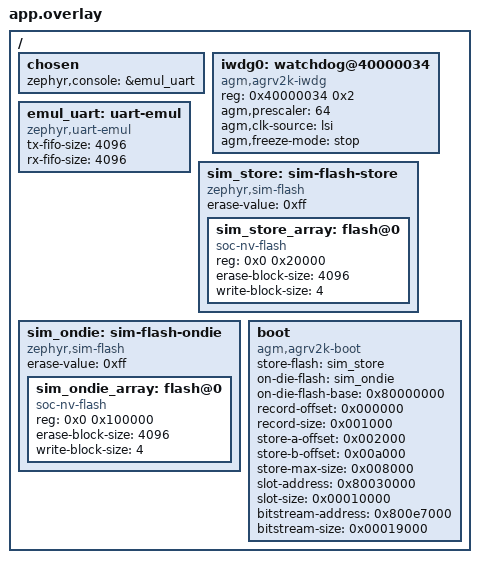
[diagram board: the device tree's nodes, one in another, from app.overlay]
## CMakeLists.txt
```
# SPDX-License-Identifier: Apache-2.0

cmake_minimum_required(VERSION 3.20.0)
find_package(Zephyr REQUIRED HINTS $ENV{ZEPHYR_BASE})
project(boot_agm_rsa)

target_sources(app PRIVATE src/main.c)

# Embed the signed-image fixtures (generated once with `imgtool sign`)
# as C arrays: the test pushes them into a simulated flash
# through the driver's own upload API, exactly like a host would.
function(agm_embed_bin out_c sym file size)
	# (${out_c} goes to the app target when it defines a symbol the driver also
	# defines weakly -- see the call for agm_boot_pubkey below.)
	file(READ "${file}" _hex HEX)
	string(REGEX REPLACE "(..)" "0x\\1," _bytes "${_hex}")
	if(size GREATER 0)
		set(_decl "const unsigned char ${sym}[${size}]")
	else()
		string(LENGTH "${_hex}" _hex_len)
		math(EXPR _n "${_hex_len} / 2")
		set(_decl "const unsigned char ${sym}[${_n}]")
	endif()
	file(WRITE "${out_c}"
"/* Generated from ${file} -- do not edit. */
#include <stddef.h>
${_decl} = {
${_bytes}
};
const size_t ${sym}_len = sizeof(${sym});
")
	zephyr_library_sources("${out_c}")
	set(AGM_LAST_GENERATED "${out_c}" PARENT_SCOPE)
endfunction()

# The driver defines `agm_boot_pubkey` weakly, and a strong definition inside
# libzephyr would not replace it: this one has to live in the app target. The
# RSA profile keeps the 270-byte PKCS#1 DER (AGM_BOOT_PUBKEY_LEN).
function(agm_embed_pubkey sym file)
	agm_embed_bin(${CMAKE_CURRENT_BINARY_DIR}/fx_pubkey.c ${sym} ${file} 270)
	target_sources(app PRIVATE "${CMAKE_CURRENT_BINARY_DIR}/fx_pubkey.c")
endfunction()

set(FIX ${CMAKE_CURRENT_SOURCE_DIR}/fixtures)
agm_embed_bin(${CMAKE_CURRENT_BINARY_DIR}/fx_signed_ok.c agm_signed_ok ${FIX}/signed_ok.bin 0)
agm_embed_bin(${CMAKE_CURRENT_BINARY_DIR}/fx_signed_other_key.c agm_signed_other_key ${FIX}/signed_other_key.bin 0)
agm_embed_bin(${CMAKE_CURRENT_BINARY_DIR}/fx_signed_other_slot.c agm_signed_other_slot ${FIX}/signed_other_slot.bin 0)
agm_embed_bin(${CMAKE_CURRENT_BINARY_DIR}/fx_raw.c agm_image_raw ${FIX}/image.bin 0)
# The ECDSA suite's signed_ok.bin, byte for byte: the *other* profile's
# container, which an RSA build has to refuse.
agm_embed_bin(${CMAKE_CURRENT_BINARY_DIR}/fx_ecdsa_signed.c agm_ecdsa_signed ${FIX}/ecdsa_signed.bin 0)
# The trusted key the driver verifies with.
agm_embed_pubkey(agm_boot_pubkey ${FIX}/pubkey.bin)
```

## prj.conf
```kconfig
# SPDX-License-Identifier: Apache-2.0
#
# The bootloader driver in its signed mode, RSA-2048-PSS flavour: images must be
# MCUboot containers signed with the fixture key (see fixtures/README.md).

CONFIG_ZTEST=y

CONFIG_FLASH=y
CONFIG_FLASH_SIMULATOR=y
CONFIG_FLASH_PAGE_LAYOUT=y
CONFIG_CRC=y
CONFIG_BOOT_AGM=y
CONFIG_BOOT_AGM_SIG_RSA2048_PSS=y

# No console protocols here; the driver still wants the console device.
CONFIG_BOOT_AGM_ONESHOT=n
CONFIG_BOOT_AGM_AN3155=n
CONFIG_SERIAL=y
# app.overlay points the console at a zephyr,uart-emul (the driver only needs
# *a* console device; this one needs no pty).
CONFIG_EMUL=y
CONFIG_UART_EMUL=y

CONFIG_MAIN_STACK_SIZE=8192
CONFIG_ZTEST_STACK_SIZE=8192

# Note: no MBEDTLS_ENABLE_HEAP here. PSA stores key material in statically
# allocated slots by default (MBEDTLS_PSA_STATIC_KEY_SLOTS), which is what a
# bootloader that imports one 270-byte public key wants -- no heap, no
# allocator in the loader's footprint.
#
# Only two of those slots: the default 16 are sized for the largest enabled
# key type and this driver imports exactly one key, so the rest is ~7.9 KB of
# RAM spent on nothing.
CONFIG_MBEDTLS_PSA_KEY_SLOT_COUNT=2
```

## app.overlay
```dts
/* SPDX-License-Identifier: Apache-2.0 */
/*
 * Devicetree for the native boot-driver test: two simulated flashes stand in
 * for the on-board SPI NOR (record + A/B stores + bitstream staging) and the
 * on-die flash (application slot + fabric reservation), and the boot node
 * describes a small layout on top of them.
 *
 * The addresses are the real ones (the on-die flash is mapped at 0x80000000
 * and the application slot sits at 0x80030000, as on the board), so the
 * driver's address-arithmetic -- slot/bitstream addresses vs device offsets,
 * and the "is this container linked for the slot I am writing it to" check --
 * is exercised too. The on-die flash node carries no `reg` (a simulated flash
 * node does not), which is what `on-die-flash-base` is for.
 */

/ {
	/* The console is an emulated UART so the tests can feed the protocol
	 * servers (AN3155, and whatever else uses the console) byte by byte and
	 * read their replies, with no pty and no timing games. */
	chosen {
		zephyr,console = &emul_uart;
	};

	/* The trial-watchdog chain . A simulated IWDG node
	 * makes CONFIG_BOOT_AGM_TRIAL_WATCHDOG selectable here; the test
	 * overrides the driver's weak hooks, so no register is ever touched. */
	iwdg0: watchdog@40000034 {
		compatible = "agm,agrv2k-iwdg";
		reg = <0x40000034 0x2>;
		agm,prescaler = <64>;
		agm,clk-source = "lsi";
		agm,freeze-mode = "stop";
		status = "okay";
	};

	emul_uart: uart-emul {
		compatible = "zephyr,uart-emul";
		status = "okay";
		/* 4 KiB each: the console upload phase prints its progress
		 * through the same emulated UART the protocol replies come
		 * out of, so the TX fifo has to hold a whole session's text
		 * plus the ACK/NAK byte the test looks at. */
		tx-fifo-size = <4096>;
		rx-fifo-size = <4096>;
	};

	sim_store: sim-flash-store {
		compatible = "zephyr,sim-flash";
		erase-value = <0xff>;
		#address-cells = <1>;
		#size-cells = <1>;
		status = "okay";

		sim_store_array: flash@0 {
			compatible = "soc-nv-flash";
			reg = <0x0 0x20000>;
			erase-block-size = <4096>;
			write-block-size = <4>;
		};
	};

	sim_ondie: sim-flash-ondie {
		compatible = "zephyr,sim-flash";
		erase-value = <0xff>;
		#address-cells = <1>;
		#size-cells = <1>;
		status = "okay";

		sim_ondie_array: flash@0 {
			compatible = "soc-nv-flash";
			reg = <0x0 0x100000>;
			erase-block-size = <4096>;
			write-block-size = <4>;
		};
	};

	boot: boot {
		compatible = "agm,agrv2k-boot";
		status = "okay";

		/* Record + stores + bitstream staging: the "external" flash. */
		store-flash = <&sim_store>;
		on-die-flash = <&sim_ondie>;
		on-die-flash-base = <0x80000000>;

		record-offset = <0x000000>;
		record-size = <0x001000>;
		store-a-offset = <0x002000>;
		store-b-offset = <0x00a000>;
		store-max-size = <0x008000>;

		slot-address = <0x80030000>;
		slot-size = <0x00010000>;

		/* The bitstream A/B geometry is the SoC's, not the layout's
		 * (soc/agm/agrv2k/agm_bitstream.h): slot 1 at 0x800b4000,
		 * slot 2 at 0x800cd000, the record sector at 0x800e6000 and
		 * the factory slot at 0x800e7000 -- so the simulated on-die
		 * flash has to be the real 1 MiB. */
		bitstream-address = <0x800e7000>;
		bitstream-size = <0x00019000>;
	};
};
```

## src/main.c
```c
/*
 * Copyright (c) 2026 AgRV Contributors
 * SPDX-License-Identifier: Apache-2.0
 */

/**
 * @file
 * @brief Signed images, RSA flavour: does the loader accept exactly the right
 *        ones?
 *
 * The same five cases as tests/drivers/misc/boot_agm_ecdsa, but against a
 * driver built with CONFIG_BOOT_AGM_SIG_RSA2048_PSS and against RSA fixtures.
 * They differ from the ECDSA ones in exactly the three places the driver has
 * profile-specific code -- the signature TLV type (0x20), the raw 256-byte
 * signature, and the KEYHASH covering the PKCS#1 DER rather than the
 * SubjectPublicKeyInfo -- so running both suites is what keeps those from
 * silently drifting apart:
 *
 *   - a properly signed MCUboot container is accepted;
 *   - one byte of payload flipped is refused (the SHA-256 TLV no longer
 *     matches);
 *   - a container signed by another key is refused (the KEYHASH TLV names a key
 *     this build does not trust);
 *   - a container that is signed by the trusted key but linked for another
 *     address is refused (the header's `ih_load_addr` is not where this layout
 *     would run it);
 *   - a raw image is refused, so a signed build cannot be downgraded by
 *     writing an unsigned one.
 */

#include <zephyr/device.h>
#include <zephyr/drivers/flash.h>
#include <zephyr/drivers/misc/boot_agm.h>
#include <zephyr/drivers/serial/uart_emul.h>
#include <zephyr/sys/byteorder.h>
#include <zephyr/sys/crc.h>
#include <zephyr/ztest.h>

#include <string.h>

#define BOOT_DEV DEVICE_DT_GET(DT_NODELABEL(boot))
#define EMUL     DEVICE_DT_GET(DT_NODELABEL(emul_uart))

extern const unsigned char agm_signed_ok[];
extern const unsigned char agm_signed_other_key[];
extern const unsigned char agm_signed_other_slot[];
extern const unsigned char agm_image_raw[];
extern const unsigned char agm_ecdsa_signed[];
extern const size_t agm_signed_ok_len;
extern const size_t agm_signed_other_key_len;
extern const size_t agm_signed_other_slot_len;
extern const size_t agm_image_raw_len;
extern const size_t agm_ecdsa_signed_len;

/* The fixtures have to be the profile this build verifies with, or the
 * "accepted" case below would be testing nothing. 270 is the PKCS#1 DER of an
 * RSA-2048 key; the ECDSA fixture is 64. */
BUILD_ASSERT(sizeof(agm_boot_pubkey) == 270,
	     "the RSA profile keeps the 270-byte PKCS#1 DER public key");

/* Push bytes into a target through the same API a host uses, tail included:
 * the flash programs whole words, so a real upload finishes with the padded
 * last word (upload_finish() does the same). */
static void place(enum agm_boot_target target, const unsigned char *data,
		  size_t len)
{
	static unsigned char padded[2048];
	size_t total = ROUND_UP(len, 4U);

	zassert_true(total <= sizeof(padded));
	memcpy(padded, data, len);
	memset(padded + len, 0xff, total - len);

	zassert_ok(agm_boot_upload_begin(BOOT_DEV, target), "upload_begin");
	for (size_t off = 0U; off < total; off += 256U) {
		size_t n = MIN(256U, total - off);

		zassert_ok(agm_boot_upload_write(BOOT_DEV, target, (uint32_t)off,
						 padded + off, (uint32_t)n),
			   "upload_write at %u", (unsigned int)off);
	}
}

ZTEST(boot_agm_rsa, test_accepts_a_properly_signed_image)
{
	place(AGM_BOOT_TARGET_STORE_A, agm_signed_ok, agm_signed_ok_len);

	{
		int ret = agm_boot_image_verify(BOOT_DEV, AGM_BOOT_TARGET_STORE_A,
						(uint32_t)agm_signed_ok_len);

		zassert_equal(ret, 0, "verify returned %d", ret);
	}
}

ZTEST(boot_agm_rsa, test_rejects_a_tampered_payload)
{
	static unsigned char tampered[2048];

	zassert_true(agm_signed_ok_len <= sizeof(tampered));
	memcpy(tampered, agm_signed_ok, agm_signed_ok_len);
	tampered[0x40] ^= 0xffU; /* inside the payload; the header is 0x20 bytes */

	place(AGM_BOOT_TARGET_STORE_A, tampered, agm_signed_ok_len);
	zassert_equal(agm_boot_image_verify(BOOT_DEV, AGM_BOOT_TARGET_STORE_A,
					    (uint32_t)agm_signed_ok_len),
		      -EACCES, "a flipped payload byte has to be refused");
}

ZTEST(boot_agm_rsa, test_rejects_another_key)
{
	place(AGM_BOOT_TARGET_STORE_A, agm_signed_other_key, agm_signed_other_key_len);

	zassert_equal(agm_boot_image_verify(BOOT_DEV, AGM_BOOT_TARGET_STORE_A,
					    (uint32_t)agm_signed_other_key_len),
		      -EACCES, "the keyhash TLV has to name a trusted key");
}

ZTEST(boot_agm_rsa, test_rejects_a_raw_image)
{
	place(AGM_BOOT_TARGET_STORE_A, agm_image_raw, agm_image_raw_len);

	zassert_equal(agm_boot_image_verify(BOOT_DEV, AGM_BOOT_TARGET_STORE_A,
					    (uint32_t)agm_image_raw_len),
		      -EINVAL, "a raw image has no MCUboot header");
}

/*
 * Rewrite the signature TLV type to the *other* profile's (RSA2048_PSS 0x20
 * <-> ECDSA_SIG 0x22), leaving the digest, the KEYHASH and the signature bytes
 * as the trusted key signed them: the profile check is the only thing left
 * that can refuse it, from the RSA side.
 */
static void stamp_signature_tlv_as(const uint8_t *src, uint32_t len, uint8_t *dst,
				   uint16_t want_type, uint16_t other_type)
{
	uint16_t hdr_size;
	uint16_t tlv_tot;
	uint32_t img_size;
	uint32_t off;
	uint32_t end;

	zassert_true(len >= 32U, "a container is at least a header");
	memcpy(dst, src, len);
	memcpy(&hdr_size, dst + 8, sizeof(hdr_size));
	memcpy(&img_size, dst + 12, sizeof(img_size));
	off = (uint32_t)hdr_size + img_size; /* the TLV area */

	zassert_true(off + 4U <= len, "the fixture has a TLV area");
	memcpy(&tlv_tot, dst + off + 2, sizeof(tlv_tot));
	end = off + tlv_tot;
	zassert_true(end <= len, "the TLV area fits the container");
	off += 4U;

	while (off + 4U <= end) {
		uint16_t type;
		uint16_t tlen;

		memcpy(&type, dst + off, sizeof(type));
		memcpy(&tlen, dst + off + 2, sizeof(tlen));
		if (type == want_type) {
			memcpy(dst + off, &other_type, sizeof(other_type));
			return;
		}
		off += 4U + tlen;
	}
	zassert_true(false, "no signature TLV in the fixture");
}

ZTEST(boot_agm_rsa, test_rejects_a_container_of_the_other_profile)
{
	place(AGM_BOOT_TARGET_STORE_A, agm_ecdsa_signed, agm_ecdsa_signed_len);

	zassert_equal(agm_boot_image_verify(BOOT_DEV, AGM_BOOT_TARGET_STORE_A,
					    (uint32_t)agm_ecdsa_signed_len),
		      -EACCES, "an ECDSA-signed container is not signed by this key");
}

ZTEST(boot_agm_rsa, test_rejects_a_relabelled_signature_tlv)
{
	static uint8_t patched[2048];

	zassert_true(agm_signed_ok_len <= sizeof(patched));
	stamp_signature_tlv_as(agm_signed_ok, (uint32_t)agm_signed_ok_len, patched,
			       0x20U /* RSA2048_PSS */, 0x22U /* ECDSA_SIG */);
	place(AGM_BOOT_TARGET_STORE_A, patched, agm_signed_ok_len);

	zassert_equal(agm_boot_image_verify(BOOT_DEV, AGM_BOOT_TARGET_STORE_A,
					    (uint32_t)agm_signed_ok_len),
		      -EINVAL, "this build takes RSA TLVs, not ECDSA ones");
}

/* The enforcement points: publish_upload() and store_boot() both call the
 * verifier, so a bad image neither reaches the record nor gets booted. */
ZTEST(boot_agm_rsa, test_publish_accepts_a_signed_image)
{
	struct agm_boot_info info;

	place(AGM_BOOT_TARGET_STORE_A, agm_signed_ok, agm_signed_ok_len);
	zassert_ok(agm_boot_upload_finish(BOOT_DEV, AGM_BOOT_TARGET_STORE_A,
					  (uint32_t)agm_signed_ok_len),
		   "a properly signed container has to publish");

	zassert_ok(agm_boot_info_get(BOOT_DEV, &info));
	zassert_true(info.record_valid);
	zassert_equal(info.slot[0].len, (uint32_t)agm_signed_ok_len);
	/* The entry point comes from the container's header, not from the host:
	 * the fixture is linked at slot + 0x20. */
	zassert_equal(info.slot[0].entry,
		      (uint32_t)DT_PROP(DT_NODELABEL(boot), slot_address) + 0x20U,
		      "entry should be derived from the MCUboot header size");
}

ZTEST(boot_agm_rsa, test_publish_refuses_a_raw_image)
{
	struct agm_boot_info before;
	struct agm_boot_info after;

	/* The suite shares one bootloader, so compare against the state this test
	 * starts with rather than assuming an empty record. */
	zassert_ok(agm_boot_info_get(BOOT_DEV, &before));

	place(AGM_BOOT_TARGET_STORE_A, agm_image_raw, agm_image_raw_len);
	zassert_true(agm_boot_upload_finish(BOOT_DEV, AGM_BOOT_TARGET_STORE_A,
					    (uint32_t)agm_image_raw_len) < 0,
		     "a raw image must not publish in a signed build");

	zassert_ok(agm_boot_info_get(BOOT_DEV, &after));
	zassert_equal(after.record_valid, before.record_valid);
	zassert_equal(after.active, before.active);
	zassert_equal(after.slot[0].len, before.slot[0].len);
	zassert_equal(after.slot[0].crc, before.slot[0].crc);
	zassert_equal(after.slot[0].state, before.slot[0].state);
	zassert_equal(after.slot[0].entry, before.slot[0].entry);
}

/* A container the trusted key really signed, but linked for another address:
 * the bytes are fine and the KEYHASH matches, so only the header's
 * `ih_load_addr` can catch it. This is the check that keeps a wrong-slot
 * upload from ever reaching the record. */
ZTEST(boot_agm_rsa, test_publish_refuses_a_container_for_another_slot)
{
	struct agm_boot_info before;
	struct agm_boot_info after;

	zassert_ok(agm_boot_info_get(BOOT_DEV, &before));

	/* It verifies as an image (signature and digest are genuine) ... */
	place(AGM_BOOT_TARGET_STORE_A, agm_signed_other_slot,
	      agm_signed_other_slot_len);
	zassert_ok(agm_boot_image_verify(BOOT_DEV, AGM_BOOT_TARGET_STORE_A,
					 (uint32_t)agm_signed_other_slot_len),
		   "the fixture has to be genuinely signed, or this tests nothing");

	/* ... but it cannot be published, because the loader would run it at
	 * slot + header size while the header says 0x80020020. */
	zassert_equal(agm_boot_upload_finish(BOOT_DEV, AGM_BOOT_TARGET_STORE_A,
					     (uint32_t)agm_signed_other_slot_len),
		      -EINVAL, "a container linked for another address must not publish");

	zassert_ok(agm_boot_info_get(BOOT_DEV, &after));
	zassert_equal(after.record_valid, before.record_valid);
	zassert_equal(after.active, before.active);
	zassert_equal(after.slot[0].len, before.slot[0].len);
	zassert_equal(after.slot[0].crc, before.slot[0].crc);
	zassert_equal(after.slot[0].state, before.slot[0].state);
	zassert_equal(after.slot[0].entry, before.slot[0].entry);
}

/* Tamper with the store *after* publishing, then ask the boot path to run it:
 * it has to refuse before copying or jumping anywhere. */
ZTEST(boot_agm_rsa, test_boot_refuses_a_store_rewritten_afterwards)
{
	static unsigned char tampered[2048];
	struct agm_boot_info info;
	uint32_t sym;
	uint32_t erase_pad;
	const struct device *store = DEVICE_DT_GET(DT_NODELABEL(sim_store));

	place(AGM_BOOT_TARGET_STORE_A, agm_signed_ok, agm_signed_ok_len);
	zassert_ok(agm_boot_upload_finish(BOOT_DEV, AGM_BOOT_TARGET_STORE_A,
					  (uint32_t)agm_signed_ok_len));
	zassert_ok(agm_boot_info_get(BOOT_DEV, &info));
	zassert_true(info.slot[0].state == AGM_BOOT_SLOT_TRIAL);

	/* Rewrite the store with a tampered copy, behind the record's back. */
	zassert_true(agm_signed_ok_len <= sizeof(tampered));
	memcpy(tampered, agm_signed_ok, agm_signed_ok_len);
	tampered[0x40] ^= 0xffU;
	sym = (uint32_t)DT_PROP(DT_NODELABEL(boot), store_a_offset);
	erase_pad = ROUND_UP((uint32_t)agm_signed_ok_len, 4096U);
	for (uint32_t off = 0U; off < erase_pad; off += 4096U) {
		zassert_ok(flash_erase(store, sym + off, 4096U));
	}
	zassert_ok(flash_write(store, sym, tampered,
			       ROUND_UP((uint32_t)agm_signed_ok_len, 4U)));

	zassert_equal(agm_boot_boot(BOOT_DEV, 0U), -EACCES,
		      "the boot path has to refuse the tampered store");
}

/* ---- the console upload protocol, and what it says when it says no ----
 *
 * Everything above calls the driver API directly, which is one layer below
 * what tools/agm_upload.py speaks. That layer has no native coverage in this
 * tree at all, and the one thing it is responsible for that the API is not is
 * *how a refusal is reported*: the bytes are in the store by the time the
 * verifier runs, so "the image was refused" and "the flash write failed" used
 * to come back as the same NAK code (3), which sent a dev board session chasing
 * the flash instead of the signature.
 *
 * The frames here are the host tool's, byte for byte (frames(): a 16-byte
 * header -- magic, command, wire target, reserved, then offset/length/CRC as
 * little-endian 32-bit fields -- followed by the payload).
 */

#define UP_MAGIC      0xA5U
#define UP_ACK        0x79U
#define UP_NAK        0x1FU
#define UP_CMD_DATA   0x01U
#define UP_CMD_FINISH 0x02U
#define UP_ERR_FLASH  3U
#define UP_ERR_REJECT 4U

static uint8_t up_rx[4096];
static uint32_t up_rx_len;
static uint8_t up_tx[4096];
static uint32_t up_tx_len;

static void up_put(const uint8_t *data, uint32_t len)
{
	zassert_true(up_rx_len + len <= sizeof(up_rx), "uart-emul RX is too small");
	memcpy(up_rx + up_rx_len, data, len);
	up_rx_len += len;
}

static void up_put32(uint32_t v)
{
	uint8_t b[4] = { (uint8_t)v, (uint8_t)(v >> 8), (uint8_t)(v >> 16),
			 (uint8_t)(v >> 24) };

	up_put(b, sizeof(b));
}

static void up_frame(uint8_t cmd, uint8_t target, uint32_t off,
		     const uint8_t *data, uint32_t len)
{
	uint8_t hdr[4] = { UP_MAGIC, cmd, target, 0U };

	up_put(hdr, sizeof(hdr));
	up_put32(off);
	up_put32(len);
	up_put32(crc32_ieee(data, len));
	up_put(data, len);
}

/* Upload @a len bytes and finish, which is where the verifier runs; the phase's
 * whole console output is left in up_tx (the console prints through the same
 * UART, so the caller looks at the tail). The DATA payloads are capped at the
 * driver's UP_MAX_PAYLOAD (AGM_BOOT_UPLOAD_CHUNK) -- a signed container is
 * bigger than one frame. */
static void up_upload(const uint8_t *data, uint32_t len)
{
	static uint8_t fin[16];
	uint32_t crc = crc32_ieee(data, len);
	uint32_t off;

	up_rx_len = 0U;
	for (off = 0U; off < len; off += AGM_BOOT_UPLOAD_CHUNK) {
		uint32_t n = MIN(AGM_BOOT_UPLOAD_CHUNK, len - off);

		up_frame(UP_CMD_DATA, 0U /* wire target 'a' */, off, data + off, n);
	}

	/* FINISH payload: total length, the host's CRC over the whole image, and
	 * the load/entry the host would like (the loader derives a container's
	 * entry from its header and overrules these). */
	memset(fin, 0, sizeof(fin));
	sys_put_le32(len, &fin[0]);
	sys_put_le32(crc, &fin[4]);
	up_frame(UP_CMD_FINISH, 0U, 0U, fin, sizeof(fin));

	uart_emul_flush_tx_data(EMUL);
	zassert_equal(uart_emul_put_rx_data(EMUL, up_rx, up_rx_len), up_rx_len,
		      "uart-emul RX fifo");
	agm_boot_upload_console(BOOT_DEV, AGM_BOOT_TARGET_STORE_A);

	memset(up_tx, 0, sizeof(up_tx));
	up_tx_len = uart_emul_get_tx_data(EMUL, up_tx, sizeof(up_tx));
	uart_emul_flush_tx_data(EMUL);
}

ZTEST(boot_agm_rsa, test_console_phase_acks_a_signed_container)
{
	up_upload(agm_signed_ok, (uint32_t)agm_signed_ok_len);

	/* The last frame's reply is the last byte the phase wrote. */
	zassert_true(up_tx_len > 0U);
	zassert_equal(up_tx[up_tx_len - 1U], UP_ACK,
		      "a properly signed container has to end on ACK");
}

ZTEST(boot_agm_rsa, test_console_phase_says_rejected_not_flash_error)
{
	/* A raw image: the bytes upload and CRC-check fine, so the only thing
	 * that can fail is the verifier -- and the code has to say so instead of
	 * reusing "flash write/verify failed" (UP_ERR_FLASH). */
	up_upload(agm_image_raw, (uint32_t)agm_image_raw_len);

	zassert_true(up_tx_len >= 2U);
	zassert_equal(up_tx[up_tx_len - 2U], UP_NAK, "a rejected image has to NAK");
	zassert_equal(up_tx[up_tx_len - 1U], UP_ERR_REJECT,
		      "and the code has to be the verifier's, not the flash's");
}

ZTEST_SUITE(boot_agm_rsa, NULL, NULL, NULL, NULL, NULL);
```
